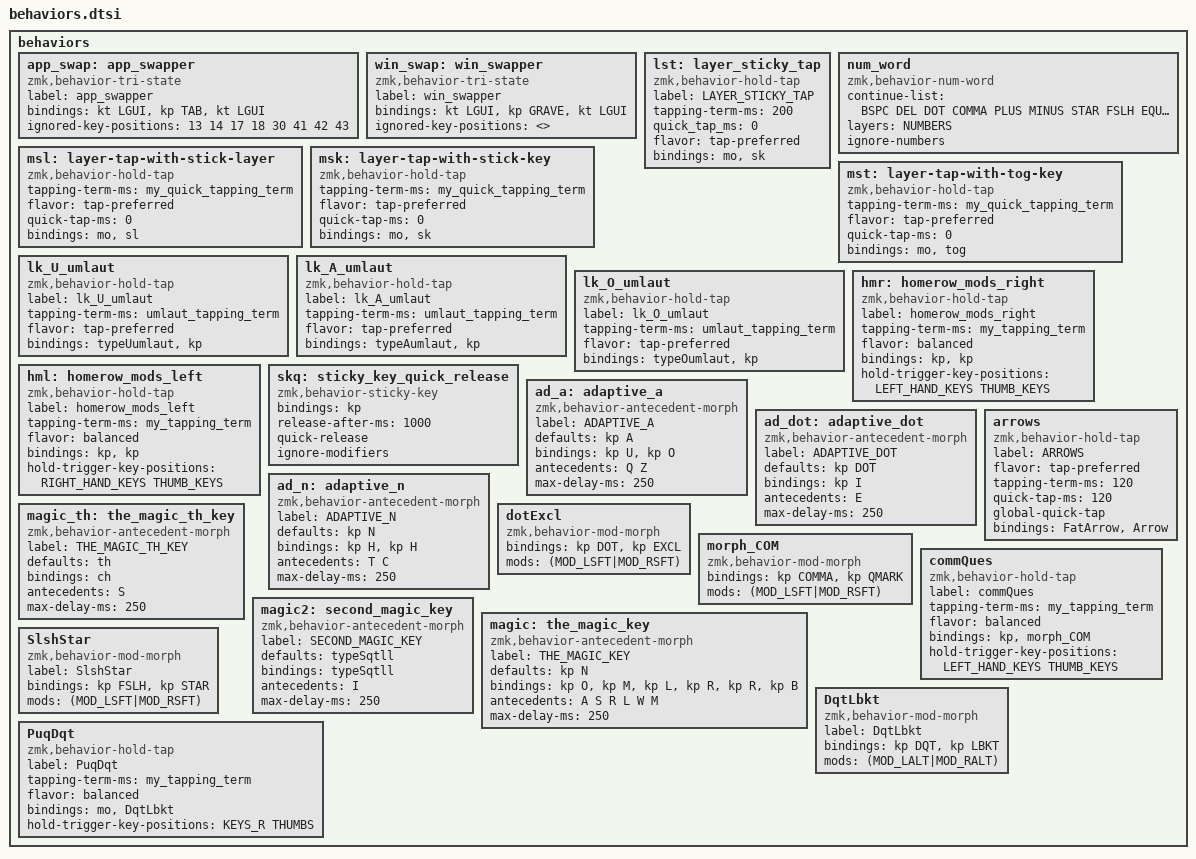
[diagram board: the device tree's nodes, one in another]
behaviors {

    app_swap: app_swapper {
        compatible = "zmk,behavior-tri-state";
        label = "app_swapper";
        #binding-cells = <0>;
        bindings = <&kt LGUI>, <&kp TAB>, <&kt LGUI>;
        ignored-key-positions = <13 14 17 18 30 41 42 43>;
    };
    win_swap: win_swapper {
        compatible = "zmk,behavior-tri-state";
        label = "win_swapper";
        #binding-cells = <0>;
        bindings = <&kt LGUI>, <&kp GRAVE>, <&kt LGUI>;
        ignored-key-positions = <>;
    };

    lst: layer_sticky_tap {
        compatible = "zmk,behavior-hold-tap";
        label = "LAYER_STICKY_TAP";
        #binding-cells = <2>;
        tapping-term-ms = <200>;
        quick_tap_ms = <0>;
        flavor = "tap-preferred";
        bindings = <&mo>, <&sk>;
    };

    // See https://github.com/dhruvinsh/zmk-num-word
    num_word: num_word {
        #binding-cells = <0>;
        compatible = "zmk,behavior-num-word";
        continue-list = <BSPC DEL DOT COMMA PLUS MINUS STAR FSLH EQUAL>;
        layers = <NUMBERS>;
        ignore-numbers;
    };

    // ********************** CUSTOM HOLD TAPS ********************** //
    // source: https://github.com/rafaelromao/keyboards/blob/main/src/zmk/features/thumbs.dtsi
    msl: layer-tap-with-stick-layer {
        compatible = "zmk,behavior-hold-tap";
        #binding-cells = <2>;
        tapping-term-ms = <my_quick_tapping_term>;
        flavor = "tap-preferred";
        quick-tap-ms = <0>;
        bindings = <&mo>, <&sl>;
    };
    msk: layer-tap-with-stick-key {
        compatible = "zmk,behavior-hold-tap";
        #binding-cells = <2>;
        tapping-term-ms = <my_quick_tapping_term>;
        flavor = "tap-preferred";
        quick-tap-ms = <0>;
        bindings = <&mo>, <&sk>;
    };
    mst: layer-tap-with-tog-key {
        compatible = "zmk,behavior-hold-tap";
        #binding-cells = <2>;
        tapping-term-ms = <my_quick_tapping_term>;
        flavor = "tap-preferred";
        quick-tap-ms = <0>;
        bindings = <&mo>, <&tog>;
    };

        lk_U_umlaut: lk_U_umlaut { // ¨, ü on "linger"
        compatible = "zmk,behavior-hold-tap";
        label = "lk_U_umlaut";
        #binding-cells = <2>;
        tapping-term-ms = <umlaut_tapping_term>;
        flavor = "tap-preferred";
        bindings = <&typeUumlaut>, <&kp>;
    };
        lk_A_umlaut: lk_A_umlaut { // ¨, ü on "linger"
        compatible = "zmk,behavior-hold-tap";
        label = "lk_A_umlaut";
        #binding-cells = <2>;
        tapping-term-ms = <umlaut_tapping_term>;
        flavor = "tap-preferred";
        bindings = <&typeAumlaut>, <&kp>;
    };
        lk_O_umlaut: lk_O_umlaut { // ¨, ü on "linger"
        compatible = "zmk,behavior-hold-tap";
        label = "lk_O_umlaut";
        #binding-cells = <2>;
        tapping-term-ms = <umlaut_tapping_term>;
        flavor = "tap-preferred";
        bindings = <&typeOumlaut>, <&kp>;
    };



    // For the "layer" key, it'd nice to be able to use it as either a shift or a toggle.
    // Configure it as a tap dance, so the first tap (or hold) is a &mo and the second tap is a &to
    // layer_td: tap_dance_0 {
    //     compatible = "zmk,behavior-tap-dance";
    //     #binding-cells = <0>;
    //     tapping-term-ms = <200>;
    //     bindings = <&mo LOWER>, <&to LOWER>;
    // };


    // Home Row Mods
    hmr: homerow_mods_right { // use on right hand to mod left
        compatible = "zmk,behavior-hold-tap";
        label = "homerow_mods_right";
        #binding-cells = <2>;
        tapping-term-ms = <my_tapping_term>;
        flavor = "balanced";
        bindings = <&kp>, <&kp>;
        hold-trigger-key-positions = <LEFT_HAND_KEYS THUMB_KEYS>; // left hand allowed
    };
   

    hml: homerow_mods_left { // use on left hand to mod right
        compatible = "zmk,behavior-hold-tap";
        label = "homerow_mods_left";
        #binding-cells = <2>;
        tapping-term-ms = <my_tapping_term>;
        flavor = "balanced";
        bindings = <&kp>, <&kp>;
        hold-trigger-key-positions = <RIGHT_HAND_KEYS THUMB_KEYS>; // right hand allowed but  not magic!
    };

    skq: sticky_key_quick_release {
        compatible = "zmk,behavior-sticky-key";
        #binding-cells = <1>;
        bindings = <&kp>;
        release-after-ms = <1000>;
        quick-release;
        ignore-modifiers;
    };
    ad_a: adaptive_a {
        compatible = "zmk,behavior-antecedent-morph";
        label = "ADAPTIVE_A";
        #binding-cells = <0>;
        defaults = <&kp A>;
        bindings = <&kp U>, <&kp O>;
        antecedents = <Q Z>;
        max-delay-ms = <250>;
    };
    ad_dot: adaptive_dot {
        compatible = "zmk,behavior-antecedent-morph";
        label = "ADAPTIVE_DOT";
        #binding-cells = <0>;
        defaults = <&kp DOT>;
        bindings = <&kp I>;
        antecedents = <E>;
        max-delay-ms = <250>;
    };

    arrows: arrows {
        compatible = "zmk,behavior-hold-tap";
        label = "ARROWS";
        #binding-cells = <2>;
        flavor = "tap-preferred";
        tapping-term-ms = <120>;
        quick-tap-ms = <120>;
        global-quick-tap;
        bindings = <&FatArrow>, <&Arrow>;
    };


    ad_n: adaptive_n {
        compatible = "zmk,behavior-antecedent-morph";
        label = "ADAPTIVE_N";
        #binding-cells = <0>;
        defaults = <&kp N>;
        bindings = <&kp H>, <&kp H>;
        antecedents = <T C>;
        max-delay-ms = <250>;
    };
    magic_th: the_magic_th_key {
        compatible = "zmk,behavior-antecedent-morph";
        label = "THE_MAGIC_TH_KEY";
        #binding-cells = <0>;
        defaults = <&th>;
        bindings = <&ch>;
        antecedents = <S>;
        max-delay-ms = <250>;
    };

    dotExcl: dotExcl {
            compatible = "zmk,behavior-mod-morph";
            #binding-cells = <0>;
            bindings = <&kp DOT>, <&kp EXCL>;
            mods = <(MOD_LSFT|MOD_RSFT)>;
    };

    morph_COM: morph_COM {
            compatible = "zmk,behavior-mod-morph";
            #binding-cells = <0>;
            bindings = <&kp COMMA>, <&kp QMARK>;
            mods = <(MOD_LSFT|MOD_RSFT)>;
    };

         // Home Row Mods with morps
    commQues: commQues { // use on right hand to mod left
        compatible = "zmk,behavior-hold-tap";
        label = "commQues";
        #binding-cells = <2>;
        tapping-term-ms = <my_tapping_term>;
        flavor = "balanced";
        bindings = <&kp>, <&morph_COM>;
        hold-trigger-key-positions = <LEFT_HAND_KEYS THUMB_KEYS>; // left hand allowed
    };

    magic2: second_magic_key {
        compatible = "zmk,behavior-antecedent-morph";
        label = "SECOND_MAGIC_KEY";
        #binding-cells = <0>;
        defaults = <&typeSqtll>;
        bindings = <&typeSqtll>
                    ;
        antecedents = <I>;
        max-delay-ms = <250>;
    };


    magic: the_magic_key {
        compatible = "zmk,behavior-antecedent-morph";
        label = "THE_MAGIC_KEY";
        #binding-cells = <0>;
        defaults = <&kp N>;
        bindings = <&kp O>
                 , <&kp M>
                 , <&kp L>
                 , <&kp R>
                 , <&kp R>
                 , <&kp B>;
        antecedents = <A S R L W M>;
        max-delay-ms = <250>;
    };
     SlshStar: SlshStar {
            compatible = "zmk,behavior-mod-morph";
            label = "SlshStar";
            #binding-cells = <0>;
            bindings = <&kp FSLH>, <&kp STAR>;
            mods = <(MOD_LSFT|MOD_RSFT)>;
    };

    DqtLbkt: DqtLbkt {
            compatible = "zmk,behavior-mod-morph";
            label = "DqtLbkt";
            #binding-cells = <0>;
            bindings = <&kp DQT>, <&kp LBKT>;
            mods = <(MOD_LALT|MOD_RALT)>;
    };

    PuqDqt: PuqDqt {
            compatible = "zmk,behavior-hold-tap";
            label = "PuqDqt";
            #binding-cells = <2>;
            tapping-term-ms = <my_tapping_term>;
            flavor = "balanced";
            bindings = <&mo>, <&DqtLbkt>;
            hold-trigger-key-positions = <KEYS_R THUMBS>; // right hand allowed
    };
};
